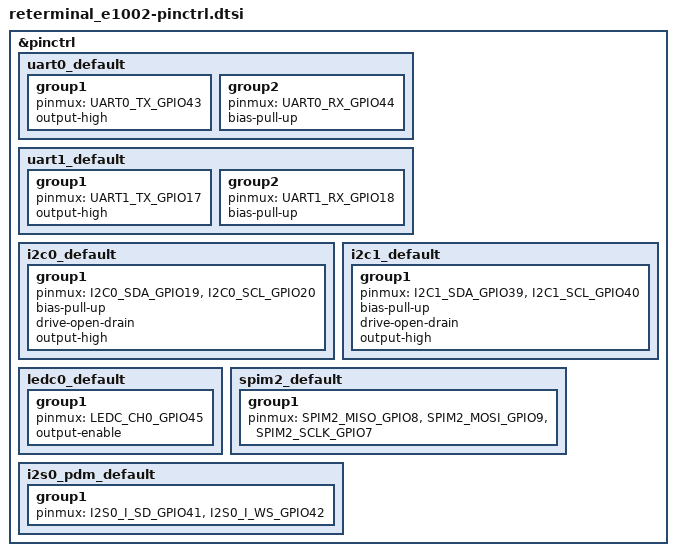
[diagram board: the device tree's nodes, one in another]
/*
 * Copyright 2025 Benjamin Lemouzy
 *
 * SPDX-License-Identifier: Apache-2.0
 */

#include <zephyr/dt-bindings/pinctrl/esp-pinctrl-common.h>
#include <zephyr/dt-bindings/pinctrl/esp32s3-pinctrl.h>
#include <zephyr/dt-bindings/pinctrl/esp32s3-gpio-sigmap.h>

&pinctrl {
	uart0_default: uart0_default {
		group1 {
			pinmux = <UART0_TX_GPIO43>;
			output-high;
		};

		group2 {
			pinmux = <UART0_RX_GPIO44>;
			bias-pull-up;
		};
	};

	uart1_default: uart1_default {
		group1 {
			pinmux = <UART1_TX_GPIO17>;
			output-high;
		};

		group2 {
			pinmux = <UART1_RX_GPIO18>;
			bias-pull-up;
		};
	};

	i2c0_default: i2c0_default {
		group1 {
			pinmux = <I2C0_SDA_GPIO19>,
				 <I2C0_SCL_GPIO20>;
			bias-pull-up;
			drive-open-drain;
			output-high;
		};
	};

	i2c1_default: i2c1_default {
		group1 {
			pinmux = <I2C1_SDA_GPIO39>,
				 <I2C1_SCL_GPIO40>;
			bias-pull-up;
			drive-open-drain;
			output-high;
		};
	};

	ledc0_default: ledc0_default {
		group1 {
			pinmux = <LEDC_CH0_GPIO45>;
			output-enable;
		};
	};

	/* SPI2 (HSPI): SD card bus per Seeed wiki (SCK=7, MOSI=9, MISO=8; CS=14 in board DTS). */
	spim2_default: spim2_default {
		group1 {
			pinmux = <SPIM2_MISO_GPIO8>,
				 <SPIM2_MOSI_GPIO9>,
				 <SPIM2_SCLK_GPIO7>;
		};
	};

	/* MSM261DHP006 PDM: DATA on GPIO41, CLK on GPIO42 (PDM_EN / MIC_PWR is GPIO38, hogged in board DTS) */
	i2s0_pdm_default: i2s0_pdm_default {
		group1 {
			pinmux = <I2S0_I_SD_GPIO41>,
				 <I2S0_I_WS_GPIO42>;
		};
	};
};
